# STM32H7R register map
File version: 1.3
CPU: CM7 r0p1, little endian, MPU, FPU, 4 interrupt priority bits
Registers are 32-bit, read-write, reset 0x0 unless marked. A register's access mark holds for its fields unless they carry their own. Offsets are from the block's base; [hi:lo] are bit positions; lines under a group give offsets from that group; {n}, {i} and the like mark numbered series; 'fields as' and 'values as' point back to an identical list.

## JPEG — JPEG codec
Base 0x52003000
0x00 CONFR0 wo — JPEG codec control register
  [0] START — Start This bit start or stop the encoding or decoding process. Note: Reads always return 0.
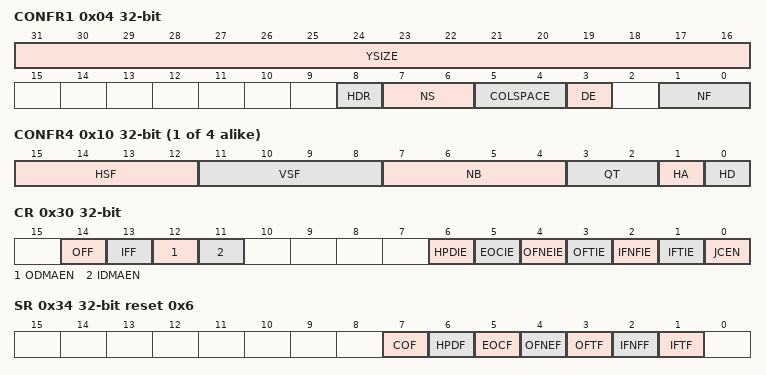
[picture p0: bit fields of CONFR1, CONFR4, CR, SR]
0x04 CONFR1 — JPEG codec configuration register 1
  [31:16] YSIZE — Y Size This field defines the number of lines in source image.
  [8] HDR — Header processing This bit enables the header processing (generation/parsing).
  [7:6] NS — Number of components for scan This field defines the number of components minus 1 for scan header marker segment.
  [5:4] COLSPACE — Color space This filed defines the number of quantization tables minus 1 to insert in the output stream.
  [3] DE — Codec operation as coder or decoder This bit selects the code or decode process
  [1:0] NF — Number of color components This field defines the number of color components minus 1.
0x08 CONFR2 — JPEG codec configuration register 2
  [25:0] NMCU — Number of MCUs For encoding: this field defines the number of MCU units minus 1 to encode. For decoding: this field indicates the number of complete MCU units minus 1 to be decoded (this field is updated after the JPEG header parsing). If the decoded image size has not a X or Y size multiple of 8 or 16 (depending on the sub-sampling process), the resulting incomplete or empty MCU must be added to this value to get the total number of MCUs generated.
0x0C CONFR3 — JPEG codec configuration register 3
  [31:16] XSIZE — X size This field defines the number of pixels per line.
{0x0+4i} CONFR{i} (i=4..7) — JPEG codec configuration register {i}
  [15:12] HSF — Horizontal sampling factor Horizontal sampling factor for component {i-4}.
  [11:8] VSF — Vertical sampling factor Vertical sampling factor for component {i-4}.
  [7:4] NB — Number of blocks Number of data units minus 1 that belong to a particular color in the MCU.
  [3:2] QT — Quantization table Selects quantization table used for component {i-4}.
  [1] HA — Huffman AC Selects the Huffman table for encoding AC coefficients.
  [0] HD — Huffman DC Selects the Huffman table for encoding DC coefficients.
0x30 CR access per field — JPEG control register
  [14] OFF wo — Output FIFO flush This bit flushes the output FIFO. Note: Reads always return 0.
  [13] IFF wo — Input FIFO flush This bit flushes the input FIFO. Note: Reads always return 0.
  [12] ODMAEN rw — Output DMA enable Enables DMA request generation for the output FIFO.
  [11] IDMAEN rw — Input DMA enable Enables DMA request generation for the input FIFO.
  [6] HPDIE rw — Header parsing done interrupt enable This bit enables interrupt generation upon the completion of the header parsing operation.
  [5] EOCIE rw — End of conversion interrupt enable This bit enables interrupt generation at the end of conversion.
  [4] OFNEIE rw — Output FIFO not empty interrupt enable This bit enables interrupt generation when the output FIFO is not empty.
  [3] OFTIE rw — Output FIFO threshold interrupt enable This bit enables interrupt generation when the output FIFO reaches a threshold.
  [2] IFNFIE rw — Input FIFO not full interrupt enable This bit enables interrupt generation when the input FIFO is not empty.
  [1] IFTIE rw — Input FIFO threshold interrupt enable This bit enables interrupt generation when the input FIFO reaches a threshold.
  [0] JCEN rw — JPEG core enable This bit enables the JPEG codec core.
0x34 SR ro reset 0x6 — JPEG status register
  [7] COF — Codec operation flag This bit flags code/decode operation in progress.
  [6] HPDF — Header parsing done flag In decode mode, this bit flags the completion of header parsing and updating internal registers.
  [5] EOCF — End of conversion flag This bit flags the completion of encode/decode process and data transfer to the output FIFO.
  [4] OFNEF — Output FIFO not empty flag This bit flags that data is available in the output FIFO. This flag must not be considered when using DMA.
  [3] OFTF — Output FIFO threshold flag This bit flags that the amount of data in the output FIFO reaches or exceeds a threshold. This flag must not be considered when using DMA.
  [2] IFNFF — Input FIFO not full flag This bit flags that the input FIFO is not full (data can be written). This flag must not be considered when using DMA.
  [1] IFTF — Input FIFO threshold flag This bit flags that the amount of data in the input FIFO is below a threshold. This flag must not be considered when using DMA.
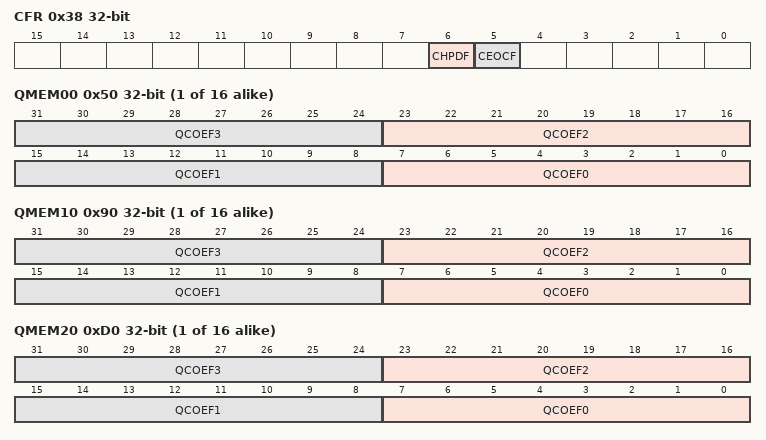
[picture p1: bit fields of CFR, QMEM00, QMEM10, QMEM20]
0x38 CFR — JPEG clear flag register
  [6] CHPDF — Clear header parsing done flag Writing 1 clears the HPDF bit of the JPEG_SR register.
  [5] CEOCF — Clear end of conversion flag Writing 1 clears the ECF bit of the JPEG_SR register.
0x40 DIR wo — JPEG data input register
  [31:0] DATAIN — Data input FIFO Input FIFO data register
0x44 DOR ro — JPEG data output register
  [31:0] DATAOUT — Data output FIFO Output FIFO data register.
{0x50+4i} QMEM0{i} (i=0..15) reset not defined — JPEG quantization memory 0
  [8n+7:8n] QCOEF{n} (n=0..3) — Quantization coefficient {n} 8-bit quantization coefficient.
{0x90+4i} QMEM1{i} (i=0..15) reset not defined — JPEG quantization memory 1
  fields as QMEM00
{0xD0+4i} QMEM2{i} (i=0..15) reset not defined — JPEG quantization memory 2
  fields as QMEM00
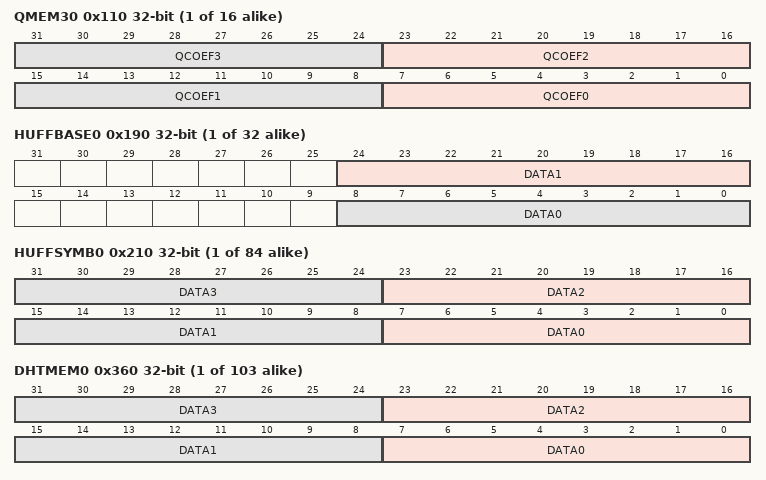
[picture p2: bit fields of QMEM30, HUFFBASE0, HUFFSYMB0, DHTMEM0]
{0x110+4i} QMEM3{i} (i=0..15) reset not defined — JPEG quantization memory 3
  fields as QMEM00
{0x150+0x10*i} HUFFMIN{i} (i=0..3) group — HUFFMIN cluster: 100-bit minimum Huffman value
  {0x0+4j} HUFFMIN_{j} reset not defined (j=0..2) — Bits {32j}-{32j+31} of the minimum Huffman value
    [31:0] DATA0 — Minimum Huffman value 100-bit minimum Huffman value used internally by the JPEG decoder.
  0x0C HUFFMIN_3 reset not defined — Bits 96-99 of the minimum Huffman value
    [3:0] DATA0 — Minimum Huffman value 100-bit minimum Huffman value used internally by the JPEG decoder.
{0x190+4i} HUFFBASE{i} (i=0..31) reset not defined — JPEG Huffman base
  [24:16] DATA1 — Data 1 Base Huffman value.
  [8:0] DATA0 — Data 0 Base Huffman value.
{0x210+4i} HUFFSYMB{i} (i=0..83) reset not defined — JPEG Huffman symbol
  [8n+7:8n] DATA{n} (n=0..3) — Data {n} Huffman symbol.
{0x360+4i} DHTMEM{i} (i=0..102) reset not defined — JPEG DHT memory
  [8n+7:8n] DATA{n} (n=0..3) — Huffman table data {n} Huffman table data for DHT marker segment generation.
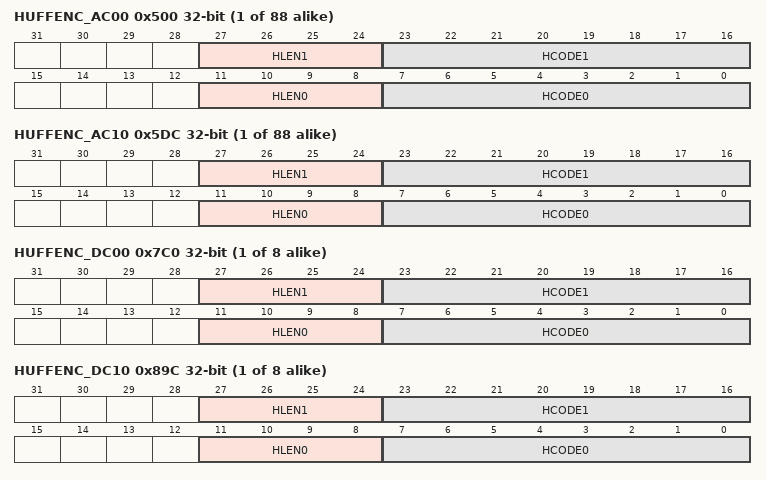
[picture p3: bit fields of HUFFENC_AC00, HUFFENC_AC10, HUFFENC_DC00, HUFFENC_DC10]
{0x500+4i} HUFFENC_AC0{i} (i=0..87) reset not defined — JPEG encoder, AC Huffman table 0
  [27:24] HLEN1 — Huffman length 1 Number of bits in the Huffman code HCODE1 minus 1.
  [23:16] HCODE1 — Huffman code 1 8 least significant bits of the Huffman code. If the Huffman code is less than 8 bits long, the unused bits must be 0.
  [11:8] HLEN0 — Huffman length 0 Number of bits in the Huffman code HCODE0 minus 1.
  [7:0] HCODE0 — Huffman code 0 8 least significant bits of the Huffman code. If the Huffman code is less than 8 bits long, the unused bits must be 0.
{0x5DC+4i} HUFFENC_AC1{i} (i=0..87) reset not defined (alternate view of HUFFENC_AC0_55) — JPEG encoder, AC Huffman table 1
  fields as HUFFENC_AC00
{0x7C0+4i} HUFFENC_DC0{i} (i=0..7) reset not defined — JPEG encoder, DC Huffman table 0
  fields as HUFFENC_AC00
{0x89C+4i} HUFFENC_DC1{i} (i=0..7) reset not defined — JPEG encoder, DC Huffman table 1
  fields as HUFFENC_AC00
